# headsail register map
Vendor: tuni.fi; File version: 1.0
CPU: other r1p0, little endian, no MPU, no FPU, vendor SysTick, 2 interrupt priority bits
Registers are 32-bit, read-write, no defined reset value unless marked. A register's access mark holds for its fields unless they carry their own. Offsets are from the block's base; [hi:lo] are bit positions; lines under a group give offsets from that group; {n}, {i} and the like mark numbered series; 'fields as' and 'values as' point back to an identical list.

## SYSCTRL
Base 0x1FF900000
0x1000 GPIO group
  0x00 DIR reset 0x0 — GPIO direction configuration bitfield: - bit[i]=1b0: Input mode for GPIO[i] - bit[i]=1b1: Output mode for GPIO[i]
  0x04 EN reset 0x0 — GPIO clock enable config register. Bit 31 - 0 GPIOEN (R/W) GPIO[31:0] clock enable configuration bitfield: - bit[i]=1b0: disable clock for GPIO[i] - bit[i]=1b1: enable clock for GPIO[i] GPIOs are gathered by groups of 4. The clock gating of one group is done only if all 4 GPIOs are disabled. Clock must be enabled for a GPIO if its direction is configured in input mode.
    [31:0] GPIOEN
  0x08 IN ro — GPIO Data IN register. Bit 31 - 0 DATA_IN (R) GPIO[31:0] input data read bitfield. DATA_IN[i] corresponds to input data of GPIO[i].
    [31:0] DATA_IN
  0x0C OUT reset 0x0 — GPIO Data out register. Bit 31 - 0 DATA_OUT (R/W) GPIO[31:0] output data read bitfield. DATA_OUT[i] corresponds to output data set on GPIO[i].
    [31:0] DATA_OUT
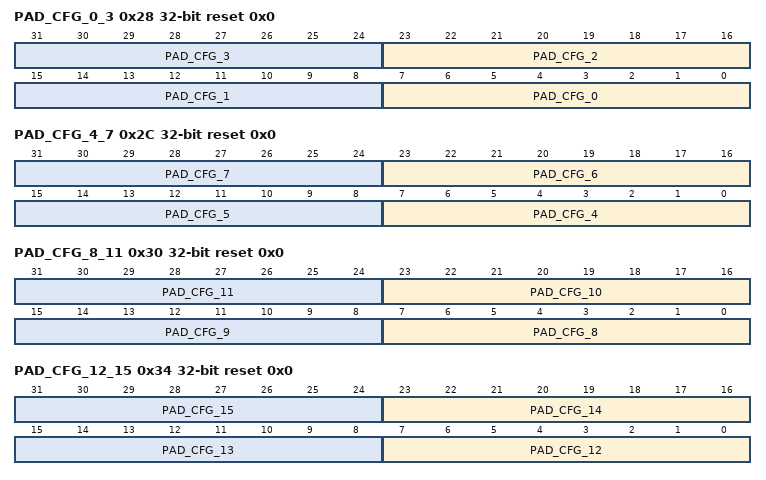
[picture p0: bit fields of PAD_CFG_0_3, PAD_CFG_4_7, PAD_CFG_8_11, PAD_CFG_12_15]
  0x28 PAD_CFG_0_3 reset 0x0 (reset mask 0xFF000000)
    [8n+7:8n] PAD_CFG_{n} (n=0..3)
  0x2C PAD_CFG_4_7 reset 0x0 (reset mask 0xFF00FF00)
    [8n-25:8n-32] PAD_CFG_{n} (n=4..7)
  0x30 PAD_CFG_8_11 reset 0x0 (reset mask 0xFF00FF00)
    [8n-57:8n-64] PAD_CFG_{n} (n=8..11)
  0x34 PAD_CFG_12_15 reset 0x0 (reset mask 0xFF00FF00)
    [8n-89:8n-96] PAD_CFG_{n} (n=12..15)
0x2000 UDMA group
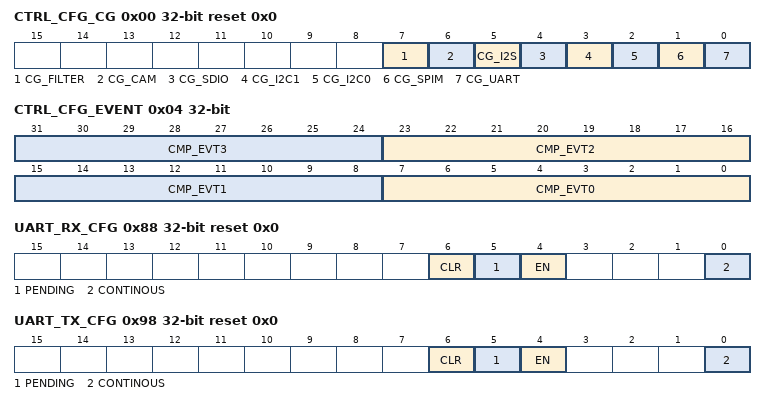
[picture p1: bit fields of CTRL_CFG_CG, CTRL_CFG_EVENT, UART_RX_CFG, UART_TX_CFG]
  0x00 CTRL_CFG_CG reset 0x0 — uDMA peripherals clock gate configuration Bitfields Defines uDMA peripherals clock gate configuration for corresponding peripheral
    [7] CG_FILTER, [6] CG_CAM, [5] CG_I2S, [4] CG_SDIO, [3] CG_I2C1, [2] CG_I2C0, [1] CG_SPIM, [0] CG_UART
  0x04 CTRL_CFG_EVENT — uDMA peripherals external event configuration
    [8n+7:8n] CMP_EVT{n} (n=0..3) — Forward event with ID matching CMP_EVT{n} to peripherals as event{n}
  0x08 CTRL_CFG_RST reset 0x0 — uDMA peripherals reset trigger (unimplemented)
  0x80 UART_RX_SADDR reset 0x0 — uDMA RX UART buffer base address configuration register
    [31:0] RX_SADDR — RX buffer base address bitfield: - Read: returns value of the buffer pointer until transfer is finished. Else returns 0. - Write: sets RX buffer base address
  0x84 UART_RX_SIZE reset 0x0 — uDMA RX UART buffer size configuration register
    [16:0] RX_SIZE — RX buffer size bitfield in bytes. (128kBytes maximum) - Read: returns remaining buffer size to transfer. - Write: sets buffer size.
  0x88 UART_RX_CFG reset 0x0 — uDMA RX UART stream configuration register
    [6] CLR wo — RX channel clear and stop transfer: -1'b0: disable -1'b1: stop and clear the on-going transfer
    [5] PENDING ro
    [4] EN — RX channel enable and start transfer bitfield: -1'b0: disable -1'b1: enable and start the transfer This signal is used also to queue a transfer if one is already ongoing.
    [0] CONTINOUS — RX channel continuous mode bitfield: -1'b0: disabled -1'b1: enabled At the end of the buffer transfer, the uDMA reloads the address / buffer size and starts a new transfer.
  0x90 UART_TX_SADDR reset 0x0 — uDMA TX UART buffer base address configuration register.
    [31:0] TX_SADDR — TX buffer base address bitfield: - Read: returns value of the buffer pointer until transfer is finished. Else returns 0. - Write: sets buffer base address
  0x94 UART_TX_SIZE reset 0x0 — uDMA TX UART buffer size configuration register
    [16:0] TX_SIZE — TX buffer size bitfield in bytes. (128kBytes maximum) - Read: returns remaining buffer size to transfer. - Write: sets buffer size.
  0x98 UART_TX_CFG reset 0x0 — uDMA TX UART stream configuration register.
    [6] CLR wo — RX channel clear and stop transfer: -1'b0: disable -1'b1: stop and clear the on-going transfer
    [5] PENDING ro — TX transfer pending in queue status flag: -1'b0: no pending transfer in the queue -1'b1: pending transfer in the queue
    [4] EN — TX channel enable and start transfer bitfield: -1'b0: disabled -1'b1: enable and start the transfer This signal is used also to queue a transfer if one is already ongoing.
    [0] CONTINOUS — TX channel continuous mode bitfield: -1'b0: disabled -1'b1: enabled At the end of the buffer transfer, the uDMA reloads the address / buffer size and starts a new transfer.
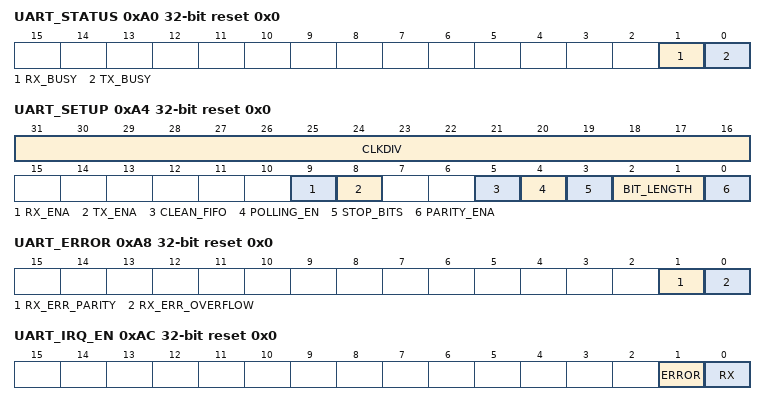
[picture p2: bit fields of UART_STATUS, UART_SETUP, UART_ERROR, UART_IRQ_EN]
  0xA0 UART_STATUS ro reset 0x0 — uDMA UART status register
    [1] RX_BUSY — RX busy status flag: - 1'b0: no RX transfer on-going - 1'b1: RX transfer on-going
    [0] TX_BUSY — TX busy status flag: - 1'b0: no TX transfer on-going - 1'b1: TX transfer on-going
  0xA4 UART_SETUP reset 0x0 (reset mask 0xFFFF0003) — UDMA UART configuration register.
    [31:16] CLKDIV — UART Clock divider configuration bitfield. The baudrate is equal to SOC_FREQ/CLKDIV.
    [9] RX_ENA — RX transceiver configuration bitfield: - 1'b0: disabled - 1'b1: enabled
    [8] TX_ENA — TX transceiver configuration bitfield: - 1'b0: disabled - 1'b1: enabled
    [5] CLEAN_FIFO — In all mode clean the RX fifo, set 1 then set 0 to realize a reset fifo: - 1'b0: Stop Clean the RX FIFO. - 1'b1: Clean the RX FIFO.
    [4] POLLING_EN — When in uart read, use polling method to read the data, read interrupt enable flag will be ignored: - 1'b0: Do not using polling method to read data. - 1'b1: Using polling method to read data. Interrupt enable flag will be ignored.
    [3] STOP_BITS — Stop bits length bitfield: - 1'b0: 1 stop bit - 1'b1: 2 stop bits
    [2:1] BIT_LENGTH — Character length bitfield: - 2'b00: 5 bits - 2'b01: 6 bits - 2'b10: 7 bits - 2'b11: 8 bits
    [0] PARITY_ENA — Parity bit generation and check configuration bitfield: - 1'b0: disabled - 1'b1: enabled
  0xA8 UART_ERROR ro reset 0x0 — uDMA UART Error status
    [1] RX_ERR_PARITY — RX parity error status flag: - 1'b0: no error - 1'b1: RX parity error occurred
    [0] RX_ERR_OVERFLOW — RX overflow error status flag: - 1'b0: no error - 1'b1: RX overflow error occurred
  0xAC UART_IRQ_EN reset 0x0 — uDMA UART Read or Error interrupt enable register
    [1] ERROR — Error interrupt in enable flag: - 1'b0: Error IRQ disable - 1'b1: Error IRQ enable
    [0] RX — Rx interrupt in enable flag: - 1'b0: RX IRQ disable - 1'b1: RX IRQ enable
  0xB0 UART_VALID ro reset 0x0 — uDMA UART Read polling data valid flag register
    [0] READY — Used only in RX polling method to indicate data is ready for read: - 1'b0: Data is not ready to read - 1'b1: Data is ready to read
  0xB4 UART_DATA ro reset 0x0 — RX read data for polling or interrupt
    [7:0] BYTE
  0x100 SPIM_RX_SADDR reset 0x0 — RX SPI uDMA transfer address of associated buffer
    [31:0] RX_SADDR — Configure pointer to memory buffer: - Read: value of the pointer until transfer is over. Else returns 0 - Write: set Address Pointer to memory buffer start address
  0x104 SPIM_RX_SIZE rw-once reset 0x0 — RX SPI uDMA transfer size of buffer
    [19:0] RX_SIZE — Buffer size in bytes. (1MBytes maximum) - Read: buffer size left - Write: set buffer size
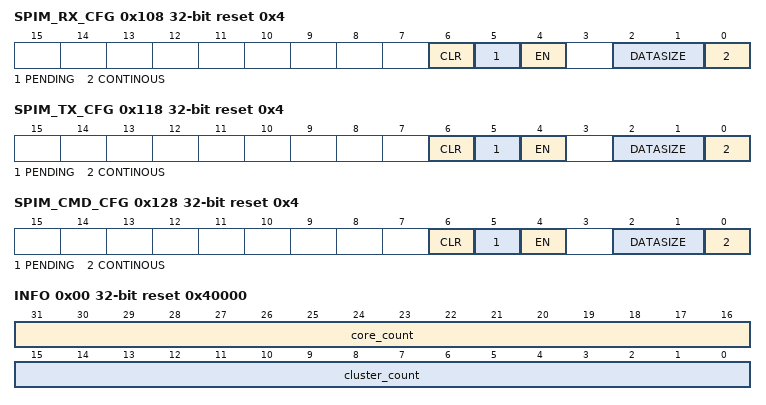
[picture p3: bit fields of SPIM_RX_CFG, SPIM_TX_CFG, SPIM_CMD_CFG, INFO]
  0x108 SPIM_RX_CFG reset 0x4 — RX SPI uDMA transfer configuration
    [6] CLR wo — Channel clear and stop transfer: -1'b0: disable -1'b1: enable
    [5] PENDING ro — Transfer pending in queue status flag: -1'b0: free -1'b1: pending
    [4] EN — Channel enable and start transfer: -1'b0: disable -1'b1: enable This signal is used also to queue a transfer if one is already ongoing
    [2:1] DATASIZE — Channel transfer size used to increment uDMA buffer address pointer: - 2'b00: +1 (8 bits) - 2'b01: +2 (16 bits) - 2'b10: +4 (
      0=8BITS; 1=16BITS; 2=32BITS
    [0] CONTINOUS — Channel continuous mode: -1'b0: disable -1'b1: enable At the end of the buffer the uDMA reloads the address and size and starts a new transfer.
  0x110 SPIM_TX_SADDR reset 0x0 — TX SPI uDMA transfer address of associated buffer
    [31:0] TX_SADDR — Configure pointer to memory buffer: - Read: value of the pointer until transfer is over. Else returns 0 - Write: set Address Pointer to memory buffer start address
  0x114 SPIM_TX_SIZE reset 0x0 — TX SPI uDMA transfer size of buffer
    [19:0] TX_SIZE — Buffer size in bytes. (1MBytes maximum) - Read: buffer size left - Write: set buffer size
  0x118 SPIM_TX_CFG reset 0x4 — TX SPI uDMA transfer configuration
    fields as UDMA.SPIM_RX_CFG
  0x120 SPIM_CMD_SADDR reset 0x0 — CMD SPI uDMA transfer address of associated buffer
    [31:0] CMD_SADDR — Configure pointer to memory buffer: - Read: value of the pointer until transfer is over. Else returns 0 - Write: set Address Pointer to memory buffer start address
  0x124 SPIM_CMD_SIZE reset 0x0 — CMD SPI uDMA transfer size of buffer
    [19:0] CMD_SIZE — Buffer size in bytes. (1MBytes maximum) - Read: buffer size left - Write: set buffer size
  0x128 SPIM_CMD_CFG reset 0x4 — CMD SPI uDMA transfer configuration
    fields as UDMA.SPIM_RX_CFG
0x4000 SocControl group
  0x00 INFO ro reset 0x40000 (reset mask 0xFFFF0000) — This register holds the number of clusters and the number of cores in the each cluster. It is a read-only register.
    [31:16] core_count — Number of Cores
    [15:0] cluster_count — Number of Clusters
  0x04 FCBOOT reset 0x1A000080 — This register holds the boot address.
    [31:0] bootaddr — Boot Start address
  0x08 FCFETCH wo reset 0x1 — This register contains the value of the fetch enable signal of the core.
    [0] fetch_enable — Enable Fetch, 1 to enable core execution
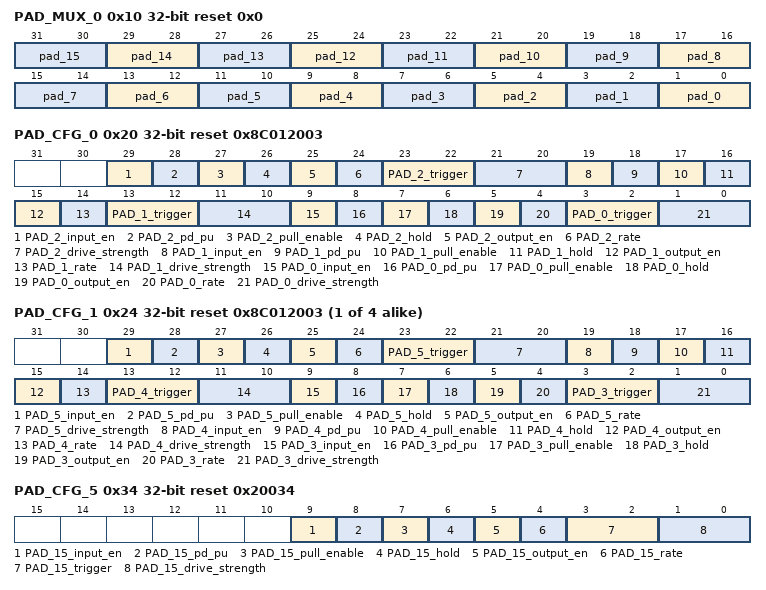
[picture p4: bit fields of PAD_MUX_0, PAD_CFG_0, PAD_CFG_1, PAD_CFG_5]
  0x10 PAD_MUX_0 reset 0x0 (reset mask 0xFF00FF00) — The content of these registers can be used to multiplex pads when targeting an ASIC. The first register (0x1A10_4010) can be used to set the mux (2 bit select) from pin 0 (bits [1:0]) to 15 (bits [31:30]).
    [2n+1:2n] pad_{n} (n=0..15)
  0x20 PAD_CFG_0 reset 0x8C012003 (reset mask 0xFC03FC03) — All 10 bit fields have reset value of 10'b10_0011_0100: 0 drive strenght 1 drive strenght 2 trigger 3 trigger 4 rate 5 output en(0) 6 hold 7 pull enable 8 pd(0)/pu(1) 9 input en(1)
    [29] PAD_2_input_en
    [28] PAD_2_pd_pu — Pull down or pull up register, default pull down 0: pull down 1: pull up
    [27] PAD_2_pull_enable
    [26] PAD_2_hold
    [25] PAD_2_output_en — 0: Enable
    [24] PAD_2_rate
    [23:22] PAD_2_trigger
    [21:20] PAD_2_drive_strength
    [19] PAD_1_input_en
    [18] PAD_1_pd_pu — Pull down or pull up register, default pull down 0: pull down 1: pull up
    [17] PAD_1_pull_enable
    [16] PAD_1_hold
    [15] PAD_1_output_en — 0: Enable
    [14] PAD_1_rate
    [13:12] PAD_1_trigger
    [11:10] PAD_1_drive_strength
    [9] PAD_0_input_en
    [8] PAD_0_pd_pu — Pull down or pull up register, default pull down 0: pull down 1: pull up
    [7] PAD_0_pull_enable
    [6] PAD_0_hold
    [5] PAD_0_output_en — 0: Enable
    [4] PAD_0_rate
    [3:2] PAD_0_trigger
    [1:0] PAD_0_drive_strength
  {0x20+4j} PAD_CFG_{j} reset 0x8C012003 (reset mask 0xFC03FC03) (j=1..4)
    [29] PAD_{3j+2}_input_en
    [28] PAD_{3j+2}_pd_pu — Pull down or pull up register, default pull down 0: pull down 1: pull up
    [27] PAD_{3j+2}_pull_enable
    [26] PAD_{3j+2}_hold
    [25] PAD_{3j+2}_output_en — 0: Enable
    [24] PAD_{3j+2}_rate
    [23:22] PAD_{3j+2}_trigger
    [21:20] PAD_{3j+2}_drive_strength
    [19] PAD_{3j+1}_input_en
    [18] PAD_{3j+1}_pd_pu — Pull down or pull up register, default pull down 0: pull down 1: pull up
    [17] PAD_{3j+1}_pull_enable
    [16] PAD_{3j+1}_hold
    [15] PAD_{3j+1}_output_en — 0: Enable
    [14] PAD_{3j+1}_rate
    [13:12] PAD_{3j+1}_trigger
    [11:10] PAD_{3j+1}_drive_strength
    [9] PAD_{3j}_input_en
    [8] PAD_{3j}_pd_pu — Pull down or pull up register, default pull down 0: pull down 1: pull up
    [7] PAD_{3j}_pull_enable
    [6] PAD_{3j}_hold
    [5] PAD_{3j}_output_en — 0: Enable
    [4] PAD_{3j}_rate
    [3:2] PAD_{3j}_trigger
    [1:0] PAD_{3j}_drive_strength
  0x34 PAD_CFG_5 reset 0x20034 (reset mask 0x300FF)
    [9] PAD_15_input_en
    [8] PAD_15_pd_pu — Pull down or pull up register, default pull down 0: pull down 1: pull up
    [7] PAD_15_pull_enable
    [6] PAD_15_hold
    [5] PAD_15_output_en — 0: Enable
    [4] PAD_15_rate
    [3:2] PAD_15_trigger
    [1:0] PAD_15_drive_strength
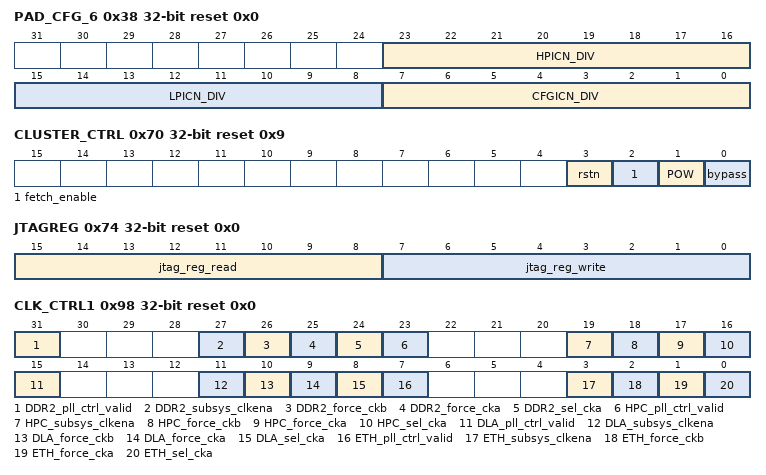
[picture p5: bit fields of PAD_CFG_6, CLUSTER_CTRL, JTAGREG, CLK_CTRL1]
  0x38 PAD_CFG_6 reset 0x0 (reset mask 0xFF00FF00) — Clock divider ratio for the 3 Interconnect modules
    [23:16] HPICN_DIV, [15:8] LPICN_DIV, [7:0] CFGICN_DIV
  0x70 CLUSTER_CTRL reset 0x9
    [3] rstn, [2] fetch_enable, [1] POW, [0] bypass
  0x74 JTAGREG reset 0x0 (reset mask 0xFF00FF) — Register to read or write from JTAG
    [15:8] jtag_reg_read, [7:0] jtag_reg_write
  0x78 CTRL_PER reset 0x0
    [0] Sel_hyper_axi
  0x7C CLUSTER_IRQ reset 0x0
    [0] Cluster_IRQ
  0x80 CLUSTER_BOOT_ADDR0 reset 0x0
  0x84 CLUSTER_BOOT_ADDR1 reset 0x0
  0x94 TOPPERIPH_CLK_DIV reset 0x0
    [15:0] REG_TOPPERIPH_CLK_DIV — Clock divider ratio for Top peripheral module
  0x98 CLK_CTRL1 reset 0x0 (reset mask 0x8F008F00) — Subsystem Clock selection. Bit definition for Ethernet, DLA; HPC, DDR2 *_CLK_CTRL Bitfield definitions [bit]:[field] 0: sel_cka 1: force_cka 2: force_ckb 3: subsys_clkena 4: - 5: - 6: - 7: pll_ctrl_valid
    [31] DDR2_pll_ctrl_valid — PLL Control valid
    [27] DDR2_subsys_clkena — Subsystem clock enable
    [26] DDR2_force_ckb — Force CKB
    [25] DDR2_force_cka — Force CKA
    [24] DDR2_sel_cka — Select CKA
    [23] HPC_pll_ctrl_valid — PLL Control valid
    [19] HPC_subsys_clkena — Subsystem clock enable
    [18] HPC_force_ckb — Force CKB
    [17] HPC_force_cka — Force CKA
    [16] HPC_sel_cka — Select CKA
    [15] DLA_pll_ctrl_valid — PLL Control valid
    [11] DLA_subsys_clkena — Subsystem clock enable
    [10] DLA_force_ckb — Force CKB
    [9] DLA_force_cka — Force CKA
    [8] DLA_sel_cka — Select CKA
    [7] ETH_pll_ctrl_valid — PLL Control valid
    [3] ETH_subsys_clkena — Subsystem clock enable
    [2] ETH_force_ckb — Force CKB
    [1] ETH_force_cka — Force CKA
    [0] ETH_sel_cka — Select CKA
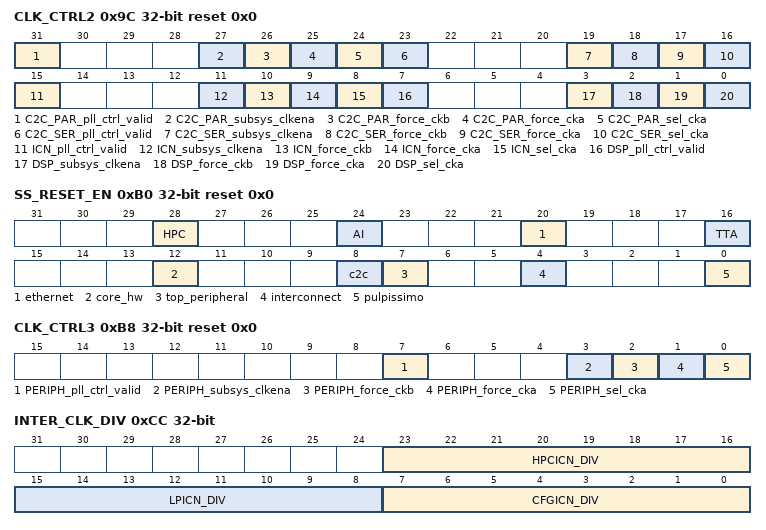
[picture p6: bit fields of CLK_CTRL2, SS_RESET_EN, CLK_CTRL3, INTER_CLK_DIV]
  0x9C CLK_CTRL2 reset 0x0 (reset mask 0x8F008F00) — Subsystem Clock selection. Bit definition for DSP, Interconnect, C2C Serial and C2C Parallel. *_CLK_CTRL Bitfield definitions [bit]:[field] 0: sel_cka 1: force_cka 2: force_ckb 3: subsys_clkena 4: - 5: - 6: - 7: pll_ctrl_valid
    [31] C2C_PAR_pll_ctrl_valid — PLL Control valid
    [27] C2C_PAR_subsys_clkena — Subsystem clock enable
    [26] C2C_PAR_force_ckb — Force CKB
    [25] C2C_PAR_force_cka — Force CKA
    [24] C2C_PAR_sel_cka — Select CKA
    [23] C2C_SER_pll_ctrl_valid — PLL Control valid
    [19] C2C_SER_subsys_clkena — Subsystem clock enable
    [18] C2C_SER_force_ckb — Force CKB
    [17] C2C_SER_force_cka — Force CKA
    [16] C2C_SER_sel_cka — Select CKA
    [15] ICN_pll_ctrl_valid — PLL Control valid
    [11] ICN_subsys_clkena — Subsystem clock enable
    [10] ICN_force_ckb — Force CKB
    [9] ICN_force_cka — Force CKA
    [8] ICN_sel_cka — Select CKA
    [7] DSP_pll_ctrl_valid — PLL Control valid
    [3] DSP_subsys_clkena — Subsystem clock enable
    [2] DSP_force_ckb — Force CKB
    [1] DSP_force_cka — Force CKA
    [0] DSP_sel_cka — Select CKA
  0xA0 CORESTATUS reset 0x0 — These 2 registers (CORESTATUS, CS_RO) contain the status of the system for testing/verification purposes like End Of Computation. The 0x1A10_40C0 register is read-only.
    [1:0] CORE_STATUS
  0xA4 SLOW_PULSE_DIV reset 0x0
    [9:0] SLOW_PULSE_DIV
  0xA8 SYSCTRL_PERIPH_CLK_DIV reset 0x0 — Controls for the peripheral clock divider within SysCtrl
    [9:0] SYSCTRL_PERIPH_CLK_DIV
  0xB0 SS_RESET_EN reset 0x0 (reset mask 0x88008800) — Assertion of the Subsystem bit, deasserts the reset to the corresponding subsystem. Bit definition is mentioned in adjoining table
    [28] HPC — HPC subsystem reset enable
    [24] AI — AI subsystem reset enable
    [20] ethernet — Ethernet subsystem reset enable
    [16] TTA — TTA Reset enable
    [12] core_hw — coreHW reset enable
    [8] c2c — C2C reset enable
    [7] top_peripheral — Top Peripheral reset enable
    [4] interconnect — interconnect subsystem reset enable
    [0] pulpissimo — Pulpissimo subsystem reset enable
  0xB8 CLK_CTRL3 reset 0x0 — Subsystem Clock selection for PERIPH *_CLK_CTRL Bitfield definitions [bit]:[field] 0: sel_cka 1: force_cka 2: force_ckb 3: subsys_clkena 4: - 5: - 6: - 7: pll_ctrl_valid
    [7] PERIPH_pll_ctrl_valid — PLL Control valid
    [3] PERIPH_subsys_clkena — Subsystem clock enable
    [2] PERIPH_force_ckb — Force CKB
    [1] PERIPH_force_cka — Force CKA
    [0] PERIPH_sel_cka — Select CKA
  0xC0 CS_RO ro reset 0x0
  0xC4 BOOTSEL ro — Boot Sel value
    [31:0] bootsel_pad
  0xC8 CLKSEL ro reset 0x0
    [31:0] CLKSEL — Irrelevant. Select FLL clock. Sysctrl does not have FLL
  0xCC INTER_CLK_DIV — Clock divider ratio for the 3 Interconnect modules.
    [23:16] HPCICN_DIV, [15:8] LPICN_DIV, [7:0] CFGICN_DIV
0x41D0 BootConfig group
  0x00 BOOT_CFG reset 0x0
    [31:0] REG_BOOT_CFG
  0x04 BOOT_STATUS reset 0x0
    [31:0] REG_BOOT_STATUS
0x4200 ETH_PLL group
  0x00 ETH_PLL_LOOP_CTRL reset 0x0
    [31:0] LOOP_CTRL
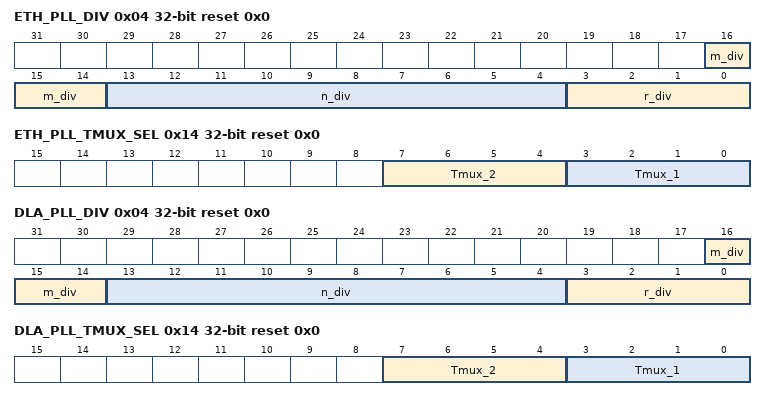
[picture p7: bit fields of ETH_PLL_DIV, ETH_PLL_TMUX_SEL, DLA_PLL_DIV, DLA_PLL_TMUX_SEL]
  0x04 ETH_PLL_DIV reset 0x0 (reset mask 0x1C03FFF)
    [16:14] m_div, [13:4] n_div, [3:0] r_div
  0x08 ETH_PLL_DEBUG_CTRL reset 0x0
    [7:0] Debug_Ctrl
  0x0C ETH_PLL_ENABLE
    [31:0] spare_ctrl
  0x10 ETH_PLL_SPARE_CTRL
    [31:0] spare_ctrl
  0x14 ETH_PLL_TMUX_SEL reset 0x0
    [7:4] Tmux_2, [3:0] Tmux_1
  0x18 ETH_PLL_STATUS1 ro reset 0x0
  0x1C ETH_PLL_STATUS2 ro reset 0x0
0x4220 DLA_PLL group
  0x00 DLA_PLL_LOOP_CTRL reset 0x0
    [31:0] LOOP_CTRL
  0x04 DLA_PLL_DIV reset 0x0 (reset mask 0x1C03FFF)
    [16:14] m_div, [13:4] n_div, [3:0] r_div
  0x08 DLA_PLL_DEBUG_CTRL reset 0x0
    [7:0] Debug_Ctrl
  0x0C DLA_PLL_ENABLE
    [31:0] spare_ctrl
  0x10 DLA_PLL_SPARE_CTRL
    [31:0] spare_ctrl
  0x14 DLA_PLL_TMUX_SEL reset 0x0
    [7:4] Tmux_2, [3:0] Tmux_1
  0x18 DLA_PLL_STATUS1 ro reset 0x0
  0x1C DLA_PLL_STATUS2 ro reset 0x0
0x4240 HPC_PLL group
  0x00 HPC_PLL_LOOP_CTRL reset 0x0
    [31:0] LOOP_CTRL
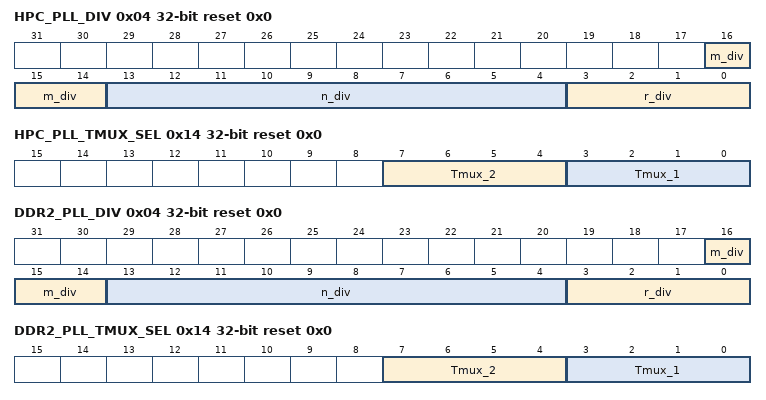
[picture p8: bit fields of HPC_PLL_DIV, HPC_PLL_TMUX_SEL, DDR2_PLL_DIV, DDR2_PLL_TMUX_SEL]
  0x04 HPC_PLL_DIV reset 0x0 (reset mask 0x1C03FFF)
    [16:14] m_div, [13:4] n_div, [3:0] r_div
  0x08 HPC_PLL_DEBUG_CTRL reset 0x0
    [7:0] Debug_Ctrl
  0x0C HPC_PLL_ENABLE
    [31:0] spare_ctrl
  0x10 HPC_PLL_SPARE_CTRL
    [31:0] spare_ctrl
  0x14 HPC_PLL_TMUX_SEL reset 0x0
    [7:4] Tmux_2, [3:0] Tmux_1
  0x18 HPC_PLL_STATUS1 ro reset 0x0
  0x1C HPC_PLL_STATUS2 ro reset 0x0
0x4260 DDR2_PLL group
  0x00 DDR2_PLL_LOOP_CTRL reset 0x0
    [31:0] LOOP_CTRL
  0x04 DDR2_PLL_DIV reset 0x0 (reset mask 0x1C03FFF)
    [16:14] m_div, [13:4] n_div, [3:0] r_div
  0x08 DDR2_PLL_DEBUG_CTRL reset 0x0
    [7:0] Debug_Ctrl
  0x0C DDR2_PLL_ENABLE
    [31:0] spare_ctrl
  0x10 DDR2_PLL_SPARE_CTRL
    [31:0] spare_ctrl
  0x14 DDR2_PLL_TMUX_SEL reset 0x0
    [7:4] Tmux_2, [3:0] Tmux_1
  0x18 DDR2_PLL_STATUS1 ro reset 0x0
  0x1C DDR2_PLL_STATUS2 ro reset 0x0
0x4280 DSP_PLL group
  0x00 DSP_LOOP_CTRL reset 0x0
    [31:0] LOOP_CTRL
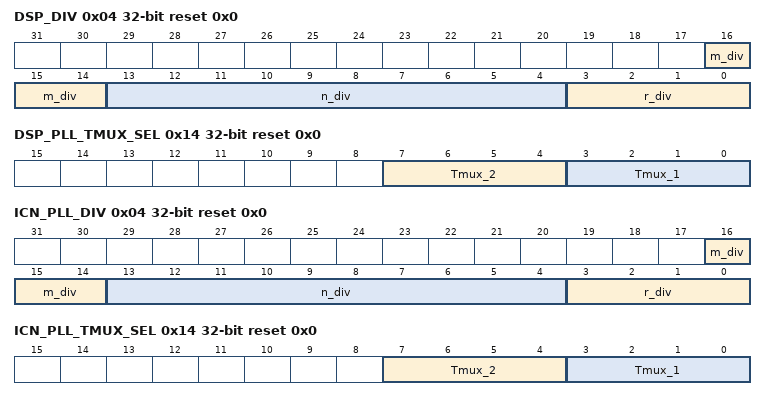
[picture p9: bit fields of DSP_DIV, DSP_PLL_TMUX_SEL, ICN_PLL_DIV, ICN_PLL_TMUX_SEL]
  0x04 DSP_DIV reset 0x0 (reset mask 0x1C03FFF)
    [16:14] m_div, [13:4] n_div, [3:0] r_div
  0x08 DSP_DEBUG_CTRL reset 0x0
    [7:0] Debug_Ctrl
  0x0C DSP_PLL_ENABLE
    [31:0] spare_ctrl
  0x10 DSP_PLL_SPARE_CTRL
    [31:0] spare_ctrl
  0x14 DSP_PLL_TMUX_SEL reset 0x0
    [7:4] Tmux_2, [3:0] Tmux_1
  0x18 DSP_PLL_STATUS1 ro reset 0x0
  0x1C DSP_PLL_STATUS2 ro reset 0x0
0x42A0 ICN_PLL group
  0x00 ICN_PLL_LOOP_CTRL reset 0x0
    [31:0] LOOP_CTRL
  0x04 ICN_PLL_DIV reset 0x0 (reset mask 0x1C03FFF)
    [16:14] m_div, [13:4] n_div, [3:0] r_div
  0x08 ICN_PLL_DEBUG_CTRL reset 0x0
    [7:0] Debug_Ctrl
  0x0C ICN_PLL_ENABLE
    [31:0] spare_ctrl
  0x10 ICN_PLL_SPARE_CTRL
    [31:0] spare_ctrl
  0x14 ICN_PLL_TMUX_SEL reset 0x0
    [7:4] Tmux_2, [3:0] Tmux_1
  0x18 ICN_PLL_STATUS1 ro reset 0x0
  0x1C ICN_PLL_STATUS2 ro reset 0x0
0x42C0 C2C_SER_PLL group
  0x00 C2C_SER_PLL_LOOP_CTRL reset 0x0
    [31:0] LOOP_CTRL
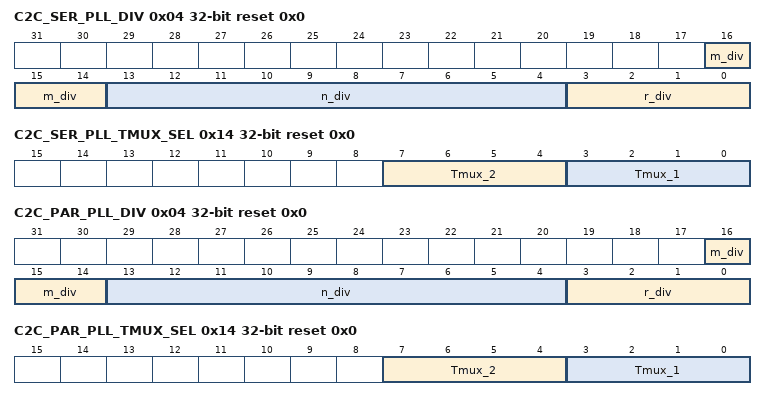
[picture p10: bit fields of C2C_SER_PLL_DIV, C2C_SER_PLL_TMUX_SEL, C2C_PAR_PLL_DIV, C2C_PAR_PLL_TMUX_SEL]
  0x04 C2C_SER_PLL_DIV reset 0x0 (reset mask 0x1C03FFF)
    [16:14] m_div, [13:4] n_div, [3:0] r_div
  0x08 C2C_SER_PLL_DEBUG_CTRL reset 0x0
    [7:0] Debug_Ctrl
  0x0C C2C_SER_PLL_ENABLE
    [31:0] spare_ctrl
  0x10 C2C_SER_PLL_SPARE_CTRL
    [31:0] spare_ctrl
  0x14 C2C_SER_PLL_TMUX_SEL reset 0x0
    [7:4] Tmux_2, [3:0] Tmux_1
  0x18 C2C_SER_PLL_STATUS1 ro reset 0x0
  0x1C C2C_SER_PLL_STATUS2 ro reset 0x0
0x42E0 C2C_PAR_PLL group
  0x00 C2C_PAR_PLL_LOOP_CTRL reset 0x0
    [31:0] LOOP_CTRL
  0x04 C2C_PAR_PLL_DIV reset 0x0 (reset mask 0x1C03FFF)
    [16:14] m_div, [13:4] n_div, [3:0] r_div
  0x08 C2C_PAR_PLL_DEBUG_CTRL reset 0x0
    [7:0] Debug_Ctrl
  0x0C C2C_PAR_PLL_ENABLE
    [31:0] spare_ctrl
  0x10 C2C_PAR_PLL_SPARE_CTRL
    [31:0] spare_ctrl
  0x14 C2C_PAR_PLL_TMUX_SEL reset 0x0
    [7:4] Tmux_2, [3:0] Tmux_1
  0x18 C2C_PAR_PLL_STATUS1 ro reset 0x0
  0x1C C2C_PAR_PLL_STATUS2 ro reset 0x0
0x4400 EMA_SS group
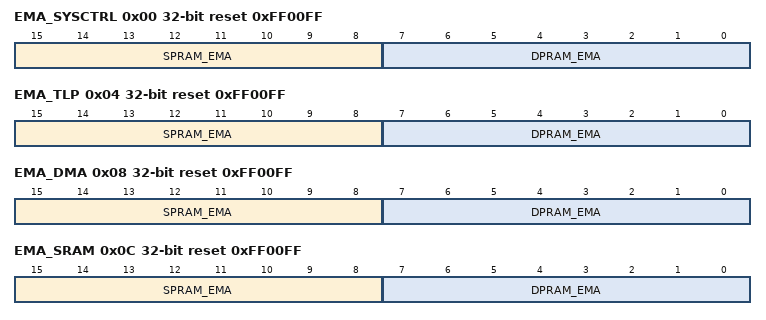
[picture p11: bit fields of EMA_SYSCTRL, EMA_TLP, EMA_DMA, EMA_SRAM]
  0x00 EMA_SYSCTRL reset 0xFF00FF (reset mask 0xFF00FF)
    [15:8] SPRAM_EMA, [7:0] DPRAM_EMA
  0x04 EMA_TLP reset 0xFF00FF (reset mask 0xFF00FF)
    [15:8] SPRAM_EMA, [7:0] DPRAM_EMA
  0x08 EMA_DMA reset 0xFF00FF (reset mask 0xFF00FF)
    [15:8] SPRAM_EMA, [7:0] DPRAM_EMA
  0x0C EMA_SRAM reset 0xFF00FF (reset mask 0xFF00FF)
    [15:8] SPRAM_EMA, [7:0] DPRAM_EMA
0x5000 AdvancedTimer group
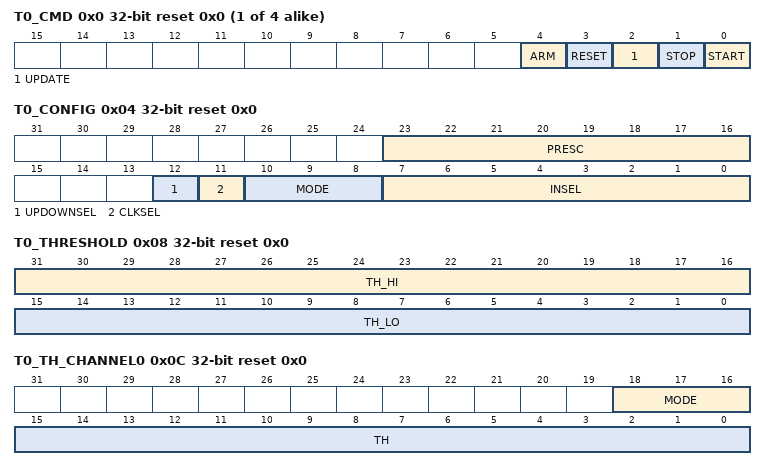
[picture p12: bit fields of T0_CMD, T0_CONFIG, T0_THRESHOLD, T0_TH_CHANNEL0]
  {0x0+0x40*j} T{j}_CMD reset 0x0 (j=0..3) — ADV_TIMER{j} command register
    [4] ARM — ADV_TIMER{j} arm command bitfield.
    [3] RESET — ADV_TIMER{j} reset command bitfield
    [2] UPDATE — ADV_TIMER{j} update command bitfield.
    [1] STOP — ADV_TIMER{j} stop command bitfield.
    [0] START — ADV_TIMER{j} start command bitfield
  0x04 T0_CONFIG reset 0x0 (reset mask 0xFF001F00) — ADV_TIMER0 configuration register.
    [23:16] PRESC — ADV_TIMER0 prescaler value configuration bitfield.
    [12] UPDOWNSEL — ADV_TIMER0 center-aligned mode configuration bitfield: - 1'b0: The counter counts up and down alternatively. - 1'b1: The counter counts up and resets to 0 when reach threshold.
    [11] CLKSEL — ADV_TIMER0 clock source configuration bitfield: - 1'b0: FLL - 1'b1: reference clock at 32kHz
    [10:8] MODE — ADV_TIMER0 trigger mode configuration bitfield: - 3'h0: trigger event at each clock cycle. - 3'h1: trigger event if input source is 0 - 3'h2: trigger event if input source is 1 - 3'h3: trigger event on input source rising edge - 3'h4: trigger event on input source falling edge - 3'h5: trigger event on input source falling or rising edge - 3'h6: trigger event on input source rising edge when armed - 3'h7: trigger event on input source falling edge when armed
    [7:0] INSEL — ADV_TIMER0 input source configuration bitfield: - 0-31: GPIO[0] to GPIO[31] - 32-35: Channel 0 to 3 of ADV_TIMER0 - 36-39: Channel 0 to 3 of ADV_TIMER1 - 40-43: Channel 0 to 3 of ADV_TIMER2 - 44-47: Channel 0 to 3 of ADV_TIMER3
  0x08 T0_THRESHOLD reset 0x0 (reset mask 0xFFFF0000) — ADV_TIMER0 threshold configuration register.
    [31:16] TH_HI — ADV_TIMER0 threshold high part configuration bitfield. It defines end counter value.
    [15:0] TH_LO — ADV_TIMER0 threshold low part configuration bitfield. It defines start counter value
  0x0C T0_TH_CHANNEL0 reset 0x0 (reset mask 0xE0001FFF) — ADV_TIMER0 channel 0 threshold configuration register
    [18:16] MODE — ADV_TIMER0 channel 0 threshold match action on channel output signal configuration bitfield: - 3'h0: set. - 3'h1: toggle then next threshold match action is clear. - 3'h2: set then next threshold match action is clear. - 3'h3: toggle. - 3'h4: clear. - 3'h5: toggle then next threshold match action is set. - 3'h6: clear then next threshold match action is set.
      0=SET; 1=TOGGLE_CLEAR_NEXT; 2=SET_CLEAR_NEXT; 3=TOGGLE; 4=CLEAR; 5=TOGGLE_SET_NEXT; 6=CLEAR_SET_NEXT
    [15:0] TH — ADV_TIMER0 channel 0 threshold configuration bitfield
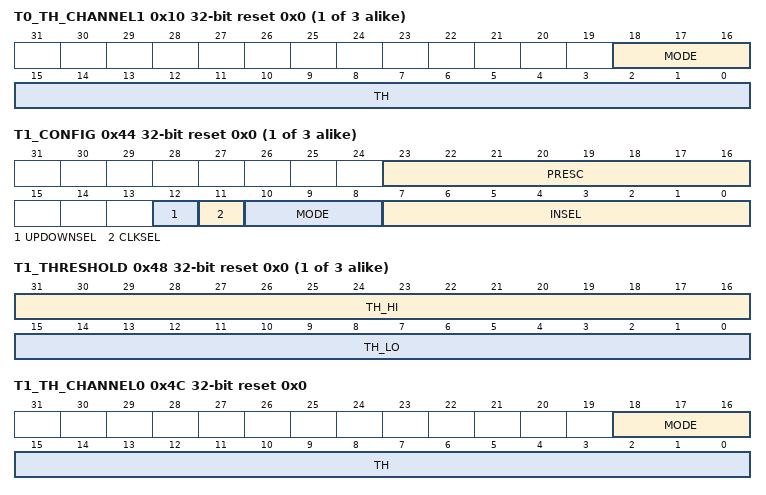
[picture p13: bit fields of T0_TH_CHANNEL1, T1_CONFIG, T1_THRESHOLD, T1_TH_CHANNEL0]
  {0xC+4j} T0_TH_CHANNEL{j} reset 0x0 (reset mask 0xE0001FFF) (j=1..3) — ADV_TIMER0 channel {j} threshold configuration register
    [18:16] MODE — ADV_TIMER0 channel {j} threshold match action on channel output signal configuration bitfield: - 3'h0: set. - 3'h1: toggle then next threshold match action is clear. - 3'h2: set then next threshold match action is clear. - 3'h3: toggle. - 3'h4: clear. - 3'h5: toggle then next threshold match action is set. - 3'h6: clear then next threshold match action is set.
      5=TOGGLE_SET_NEXT; 1=TOGGLE_CLEAR_NEXT; 3=TOGGLE; 2=SET_CLEAR_NEXT; 0=SET; 6=CLEAR_SET_NEXT; 4=CLEAR
    [15:0] TH — ADV_TIMER0 channel {j} threshold configuration bitfield
  0x2C T0_COUNTER ro reset 0x0 — ADV_TIMER0 counter register
  {0x4+0x40*j} T{j}_CONFIG reset 0x0 (reset mask 0xFF001F00) (j=1..3) — ADV_TIMER{j} configuration register
    [23:16] PRESC — ADV_TIMER{j} prescaler value configuration bitfield.
    [12] UPDOWNSEL — ADV_TIMER{j} center-aligned mode configuration bitfield: - 1'b0: The counter counts up and down alternatively. - 1'b1: The counter counts up and resets to 0 when reach threshold.
    [11] CLKSEL — ADV_TIMER{j} clock source configuration bitfield: - 1'b0: FLL - 1'b1: reference clock at 32kHz
    [10:8] MODE — ADV_TIMER{j} trigger mode configuration bitfield: - 3'h0: trigger event at each clock cycle. - 3'h1: trigger event if input source is 0 - 3'h2: trigger event if input source is 1 - 3'h3: trigger event on input source rising edge - 3'h4: trigger event on input source falling edge - 3'h5: trigger event on input source falling or rising edge - 3'h6: trigger event on input source rising edge when armed - 3'h7: trigger event on input source falling edge when armed
    [7:0] INSEL — ADV_TIMER{j} input source configuration bitfield: - 0-31: GPIO[0] to GPIO[31] - 32-35: Channel 0 to 3 of ADV_TIMER0 - 36-39: Channel 0 to 3 of ADV_TIMER1 - 40-43: Channel 0 to 3 of ADV_TIMER2 - 44-47: Channel 0 to 3 of ADV_TIMER3
  {0x8+0x40*j} T{j}_THRESHOLD reset 0x0 (reset mask 0xFFFF0000) (j=1..3) — ADV_TIMER{j} threshold configuration register
    [31:16] TH_HI — ADV_TIMER{j} threshold high part configuration bitfield. It defines end counter value.
    [15:0] TH_LO — ADV_TIMER{j} threshold low part configuration bitfield. It defines start counter value
  0x4C T1_TH_CHANNEL0 reset 0x0 (reset mask 0xE0001FFF) — ADV_TIMER1 channel 0 threshold configuration register
    [18:16] MODE — ADV_TIMER1 channel 0 threshold match action on channel output signal configuration bitfield: - 3'h0: set. - 3'h1: toggle then next threshold match action is clear. - 3'h2: set then next threshold match action is clear. - 3'h3: toggle. - 3'h4: clear. - 3'h5: toggle then next threshold match action is set. - 3'h6: clear then next threshold match action is set.
      values as AdvancedTimer.T0_TH_CHANNEL1.MODE
    [15:0] TH — ADV_TIMER1 channel 0 threshold configuration bitfield
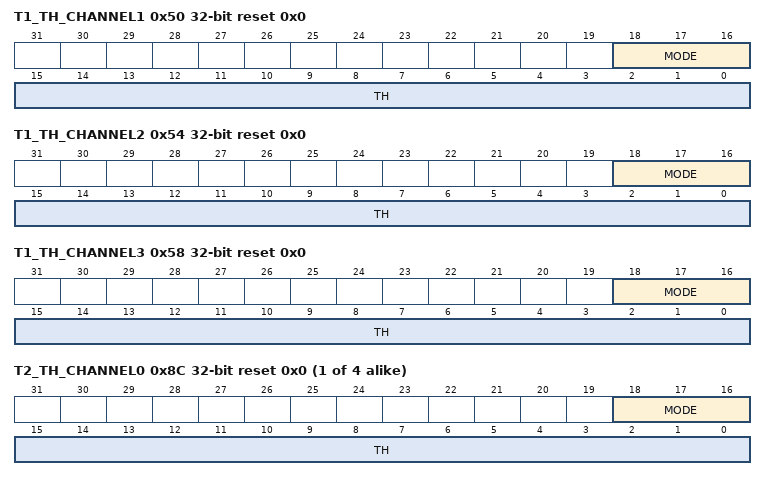
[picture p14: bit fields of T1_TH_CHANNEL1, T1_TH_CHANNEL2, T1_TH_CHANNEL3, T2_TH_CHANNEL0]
  0x50 T1_TH_CHANNEL1 reset 0x0 (reset mask 0xE0001FFF) — ADV_TIMER1 channel 1 threshold configuration register
    [18:16] MODE — ADV_TIMER1 channel 1 threshold match action on channel output signal configuration bitfield: - 3'h0: set. - 3'h1: toggle then next threshold match action is clear. - 3'h2: set then next threshold match action is clear. - 3'h3: toggle. - 3'h4: clear. - 3'h5: toggle then next threshold match action is set. - 3'h6: clear then next threshold match action is set.
      2=SET_CLEAR_NEXT; 4=CLEAR; 0=SET; 5=TOGGLE_SET_NEXT; 6=CLEAR_SET_NEXT; 1=TOGGLE_CLEAR_NEXT; 3=TOGGLE
    [15:0] TH — ADV_TIMER1 channel 1 threshold configuration bitfield
  0x54 T1_TH_CHANNEL2 reset 0x0 (reset mask 0xE0001FFF) — ADV_TIMER1 channel 2 threshold configuration register
    [18:16] MODE — ADV_TIMER2 channel 1 threshold match action on channel output signal configuration bitfield: - 3'h0: set. - 3'h1: toggle then next threshold match action is clear. - 3'h2: set then next threshold match action is clear. - 3'h3: toggle. - 3'h4: clear. - 3'h5: toggle then next threshold match action is set. - 3'h6: clear then next threshold match action is set.
      values as AdvancedTimer.T0_TH_CHANNEL1.MODE
    [15:0] TH — ADV_TIMER2 channel 1 threshold configuration bitfield
  0x58 T1_TH_CHANNEL3 reset 0x0 (reset mask 0xE0001FFF) — ADV_TIMER1 channel 3 threshold configuration register
    [18:16] MODE — ADV_TIMER1 channel 3 threshold match action on channel output signal configuration bitfield: - 3'h0: set. - 3'h1: toggle then next threshold match action is clear. - 3'h2: set then next threshold match action is clear. - 3'h3: toggle. - 3'h4: clear. - 3'h5: toggle then next threshold match action is set. - 3'h6: clear then next threshold match action is set.
      values as AdvancedTimer.T0_TH_CHANNEL1.MODE
    [15:0] TH — ADV_TIMER1 channel 3 threshold configuration bitfield
  0x6C T1_COUNTER ro reset 0x0 — ADV_TIMER1 counter register
  {0x8C+4j} T2_TH_CHANNEL{j} reset 0x0 (reset mask 0xE0001FFF) (j=0..3) — ADV_TIMER2 channel {j} threshold configuration register
    [18:16] MODE — ADV_TIMER2 channel {j} threshold match action on channel output signal configuration bitfield: - 3'h0: set. - 3'h1: toggle then next threshold match action is clear. - 3'h2: set then next threshold match action is clear. - 3'h3: toggle. - 3'h4: clear. - 3'h5: toggle then next threshold match action is set. - 3'h6: clear then next threshold match action is set.
      values as AdvancedTimer.T0_TH_CHANNEL1.MODE
    [15:0] TH — ADV_TIMER2 channel {j} threshold configuration bitfield
  0xAC T2_COUNTER reset 0x0 — ADV_TIMER2 counter register
  {0xCC+4j} T3_TH_CHANNEL{j} reset 0x0 (reset mask 0xE0001FFF) (j=0..3) — ADV_TIMER3 channel {j} threshold configuration register
    [18:16] MODE — ADV_TIMER3 channel {j} threshold match action on channel output signal configuration bitfield: - 3'h0: set. - 3'h1: toggle then next threshold match action is clear. - 3'h2: set then next threshold match action is clear. - 3'h3: toggle. - 3'h4: clear. - 3'h5: toggle then next threshold match action is set. - 3'h6: clear then next threshold match action is set.
      values as AdvancedTimer.T0_TH_CHANNEL1.MODE
    [15:0] TH — ADV_TIMER3 channel {j} threshold configuration bitfield
  0xEC T3_COUNTER ro reset 0x0 — ADV_TIMER3 counter register
  0x100 EVENT_CFG reset 0x0 — ADV_TIMERS events configuration register.
  0x104 CG reset 0x0 — ADV_TIMERS channels clock gating configuration register.
    [15:0] ENA — ADV_TIMER clock gating configuration bitfield. - ENA[i]=0: clock gate ADV_TIMERi. - ENA[i]=1: enable ADV_TIMERi.
0x6000 SocEventGenerator group
  0x00 SW_EVENT wo reset 0x0 — SoC software events trigger register
    [7:0] EVENT — Writing a one-hot value into EVENT triggers a SoC software event. 8 software events are available.
  {0x4+4j} FC_MASK{j} reset 0xFFFFFFFF (j=0..5) — Events {32j}-{32j+31} dispatch mask to FC
    [31:0] FC_MASK{j} — Event Mask to enable/disable event dispatch to FC interrupt controller. Setting bit[i] to 0b1 disables dispatching event to FC interrupt controller. Setting bit[i] to 0b0 enables dispatching event to FC interrupt controller.
  0x1C FC_MASK6 reset 0xFFFFFFFF — Events 191-223 dispatch mask to FC
    [31:0] FC_MASK6 — Event Mask to enable/disable event dispatch to FC interrupt controller. Setting bit[i] to 0b1 disables dispatching event to FC interrupt controller. Setting bit[i] to 0b0 enables dispatching event to FC interrupt controller.
  0x20 FC_MASK7 reset 0xFFFFFFFF — F Events 224-255 dispatch mask to peripherals
    [31:0] FC_MASK7 — Event Mask to enable/disable event dispatch to FC interrupt controller. Setting bit[i] to 0b1 disables dispatching event to FC interrupt controller. Setting bit[i] to 0b0 enables dispatching event to FC interrupt controller.
  0x44 PR_MASK0 reset 0xFFFFFFFF — Events 0-31 dispatch mask to peripherals
  0x48 PR_MASK1 reset 0xFFFFFFFF
    [31:0] PR_MASK1 — Event Mask to enable/disable event dispatch to peripherals. Setting bit[i] to 0b1 disables dispatching event to peripherals. Setting bit[i] to 0b0 enables dispatching event to peripherals.
  0x4C PR_MASK2 reset 0xFFFFFFFF — Events 0-31 dispatch mask to peripheralsEvents 64-95 dispatch mask to peripherals
    [31:0] PR_MASK2 — Event Mask to enable/disable event dispatch to peripherals. Setting bit[i] to 0b1 disables dispatching event to peripherals. Setting bit[i] to 0b0 enables dispatching event to peripherals.
  0x50 PR_MASK3 reset 0xFFFFFFFF — Events 96-127 dispatch mask to peripherals
    [31:0] PR_MASK3 — Event Mask to enable/disable event dispatch to peripherals. Setting bit[i] to 0b1 disables dispatching event to peripherals. Setting bit[i] to 0b0 enables dispatching event to peripherals.
  0x54 PR_MASK4 reset 0xFFFFFFFF — Events 128-159 dispatch mask to peripheral
    [31:0] PR_MASK4 — Event Mask to enable/disable event dispatch to peripherals. Setting bit[i] to 0b1 disables dispatching event to peripherals. Setting bit[i] to 0b0 enables dispatching event to peripherals.
  0x58 PR_MASK5 reset 0xFFFFFFFF — Events 160-191 dispatch mask to peripherals
    [31:0] PR_MASK5 — Event Mask to enable/disable event dispatch to peripherals. Setting bit[i] to 0b1 disables dispatching event to peripherals. Setting bit[i] to 0b0 enables dispatching event to peripherals.
  0x5C PR_MASK6 reset 0xFFFFFFFF — Events 191-223 dispatch mask to peripherals
    [31:0] PR_MASK6 — Event Mask to enable/disable event dispatch to peripherals. Setting bit[i] to 0b1 disables dispatching event to peripherals. Setting bit[i] to 0b0 enables dispatching event to peripherals.
  0x60 PR_MASK7 reset 0xFFFFFFFF — Events 224-255 dispatch mask to peripherals
    [31:0] PR_MASK7 — Event Mask to enable/disable event dispatch to peripherals. Setting bit[i] to 0b1 disables dispatching event to peripherals. Setting bit[i] to 0b0 enables dispatching event to peripherals.
  0x64 ERR0 ro reset 0x0 — Events 0-31 event queue overflow
    [31:0] ERR0 — Event queue overflow. Clear after read. Reading 0b1 at ERR[i] means the event queue of event with id i overflowed.
  0x68 ERR1 ro reset 0x0 — Events 32-63 event queue overflow
    [31:0] ERR1 — Event queue overflow. Clear after read. Reading 0b1 at ERR[i] means the event queue of event with id i overflowed.
  0x6C ERR2 ro reset 0x0 — Events 64-95 event queue overflow
    [31:0] ERR02 — Event queue overflow. Clear after read. Reading 0b1 at ERR[i] means the event queue of event with id i overflowed.
  {0x64+4j} ERR{j} ro reset 0x0 (j=3..5) — Events {32j}-{32j+31} event queue overflow
    [31:0] ERR{j} — Event queue overflow. Clear after read. Reading 0b1 at ERR[i] means the event queue of event with id i overflowed.
  0x7C ERR6 ro reset 0x0 — Events 191-223 event queue overflow
    [31:0] ERR6 — Event queue overflow. Clear after read. Reading 0b1 at ERR[i] means the event queue of event with id i overflowed.
  0x80 ERR7 ro reset 0x0 — Events 224-255 event queue overflow
  0x84 TIMER_LO access not given reset 0x0
    [7:0] TIMER_LO_EVENT — Trigger and start APB Timer LO by the event with id that equals TIMER_LO_EVENT
  0x88 TIMER_HI access not given reset 0x0 — Trigger Timer HI of APB Timer with event
    [7:0] TIMER_HI_EVENT — Trigger and start APB Timer HI by the event with id that equals TIMER_HI_EVENT
0x9000 EventInterruptUnit group
  0x00 MASK_read access not given reset 0x0 — This register contains the MASK (interrupt enable) for each of the 32 interrupts or events. Writing to 0x1A10_9004 sets the bits of the MASK register selected Writing to 0x1A10_9008 clears the bits of the MASK register selected.
    [31:0] MASK
  0x04 MASK_set access not given reset 0x0 — This register contains the MASK (interrupt enable) for each of the 32 interrupts or events. Writing to 0x1A10_9004 sets the bits of the MASK register selected. Writing to 0x1A10_9008 clears the bits of the MASK register selected.
  0x08 MASK_clear access not given reset 0x0 — This register contains the MASK (interrupt enable) for each of the 32 interrupts or events. Writing to 0x1A10_9004 sets the bits of the MASK register selected. Writing to 0x1A10_9008 clears the bits of the MASK register selected.
  0x0C INT_read access not given reset 0x0 — This register contains the pending interrupts or events. Writing to 0x1A10_9010 sets the bits of the INT register selected. Writing to 0x1A10_9014 clears the bits of the INT register selected.
  0x10 INT_set access not given reset 0x0 — INT_read
  0x14 INT_clear access not given reset 0x0
  0x18 ACK_read access not given reset 0x0 — This register contains the ACK (interrupt enable) for each of the 32 interrupts or events. Writing to 0x1A10_901C sets the bits of the ACK register selected. Writing to 0x1A10_9020 clears the bits of the ACK register selected.
  0x1C ACK_set access not given reset 0x0 — This register contains the ACK (interrupt enable) for each of the 32 interrupts or events. Writing to 0x1A10_901C sets the bits of the ACK register selected. Writing to 0x1A10_9020 clears the bits of the ACK register selected.
  0x20 ACK_clear access not given reset 0x0 — This register contains the ACK (interrupt enable) for each of the 32 interrupts or events. Writing to 0x1A10_901C sets the bits of the ACK register selected. Writing to 0x1A10_9020 clears the bits of the ACK register selected.
  0x24 FIFO_DATA ro reset 0x0 — Fifo Content. This is a read-only register that contain the first valid value of the FIFO.
    [31:0] FIFO_DATA — This is a read-only register that contain the first valid value of the FIFO
0xB000 Timer group
  0x00 CFG_LO reset 0x0 (reset mask 0x80000000) — Timer Low Configuration register
    [31] CASC — Timer low and Timer high 64-bit cascaded mode enable bit
    [15:8] PVAL — Timer low prescaler value. ftimer = fclk/(1 + P V AL)
    [7] CCFG — Timer low clock source configuration 0b0: FLL or FLL plus Prescaler 0b1: 32 kHz reference clock
    [6] PEN — Timer low prescaler enable bit
    [5] ONES — Timer low one shot configuration
    [4] MODE — Timer low continuous mode configuration 0b0: Continue incrementing timer low counter after a compare match with CMP_LO 0b1: Reset timer to after a compare match with CMP_LO
    [2] IRQEN — Timer low interrupt generation on compare match enable
    [1] RST — Timer low reset, cleared after the reset happened
    [0] EN — Timer enable (starts couting) bit
  0x04 CFG_HI reset 0x0 (reset mask 0xFF00F7) — Timer High Configuration register
    [15:8] PVAL — Timer hi prescaler value. ftimer = fclk/(1 + PVAL)
    [7] CCFG — Timer hi clock source configuration 0b0: FLL or FLL plus Prescaler 0b1: 32 kHz reference clock
    [6] PEN — Timer hi prescaler enable bit
    [5] ONES — Timer hi one shot configuration
    [4] MODE — Timer hi continuous mode configuration 0b0: Continue incrementing timer hi counter after a compare match with CMP_HI 0b1: Reset timer to after a compare match with CMP_HI
    [2] IRQEN — Timer hi interrupt generation on compare match enable
    [1] RST — Timer high reset, cleared after the reset happened
    [0] EN — Timer enable (starts couting) bit
  0x08 CNT_LO reset 0x0 — Timer Low counter value register
  0x0C CNT_HI reset 0x0 — Timer High counter value register
  0x10 CMP_LO reset 0x0 — Timer Low comparator value register
  0x14 CMP_HI reset 0x0 — Timer High comparator value register
  0x18 START_LO reset 0x0 — Start Timer Low counting register
    [0] START_LO — Timer high start command (sets EN in CFG_LO)
  0x1C START_HI reset 0x0 — Start Timer High counting register
    [0] START_HI — Timer high reset command (writes RST in CFG_LO)
  0x20 RESET_LO reset 0x0 — Reset Timer Low counter register
    [0] RESET_LO
  0x24 RESET_HI reset 0x0 — Reset Timer High counter register
    [0] RESET_HI
0x20000 SDIO group
  0x20 CMD_OP wo reset 0x0 (reset mask 0x3F0007)
    [13:8] CMD_OPCODE
    [2:0] RSP_TYPE — Values for RSP_TYPE: 3'b000: RSP_TYPE_NULL 3'b001: RSP_TYPE_48_CRC 3'b010: RSP_TYPE_48_NOCRC 3'b011: RSP_TYPE_136 3'b100: RSP_TYPE_48_BSY
      0=RSP_TYPE_NULL; 1=RSP_TYPE_48_CRC; 2=RSP_TYPE_48_NOCRC; 3=RSP_TYPE_136; 4=RSP_TYPE_48_BSY
  0x24 CMD_ARG wo reset 0x0
    [31:0] CMD_ARGUMENT
  0x28 DATA_SETUP wo reset 0x0 (reset mask 0xFFC03FC0)
    [25:16] BLOCK_SIZE, [15:8] Block_Num, [7:2] QUAD, [1] RWN, [0] EN
  0x2C START wo reset 0x0
    [0] START
  {0x30+4j} RSP{j} ro reset 0x0 (j=0..3)
    [31:0] RESPONSE_WORD{j}
  0x40 CLK_DIV_0 reset 0x0 (reset mask 0x100FF)
    [8] Valid, [7:0] Div_count
  0x44 STATUS reset 0x10 (reset mask 0xFFFF00F0)
    [31:16] Status
    [15:12] VHS — Note: Is reset value correct?
    [11:2] CARD_ERR
    [1] ERR
    [0] EOT
  0x48 CID0 ro reset 0x0 — Card Identification Word0
    [31:0] card_id_word0
  {0x48+4j} CID{j} ro reset 0x0 (j=1..3) — Card Identification Word {j}
    [31:0] card_id_word{j}
  0x58 RCA ro reset 0x0
    [15:0] RCA
  0x5C STOP wo reset 0x0
    [31] STOP
